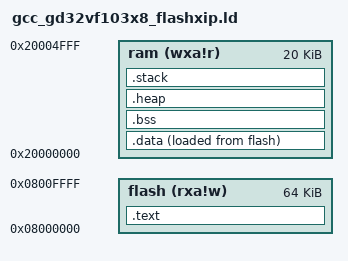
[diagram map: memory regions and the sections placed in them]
/*
 * Copyright (C) 2021 Sergey Koshkin <koshkin.sergey@gmail.com>
 * All rights reserved.
 *
 * SPDX-License-Identifier: Apache-2.0
 *
 * Licensed under the Apache License, Version 2.0 (the License); you may
 * not use this file except in compliance with the License.
 * You may obtain a copy of the License at
 *
 * www.apache.org/licenses/LICENSE-2.0
 *
 * Unless required by applicable law or agreed to in writing, software
 * distributed under the License is distributed on an AS IS BASIS, WITHOUT
 * WARRANTIES OR CONDITIONS OF ANY KIND, either express or implied.
 * See the License for the specific language governing permissions and
 * limitations under the License.
 */

/*********** Use Configuration Wizard in Context Menu *************************/

OUTPUT_ARCH( "riscv" )
/********************* Flash Configuration ************************************
 * <h> Flash Configuration
 * <o0> Flash Base Address <0x0-0xFFFFFFFF:8>
 * <o1> Flash Size (in Bytes) <0x0-0xFFFFFFFF:8>
 * </h>
 */
__ROM_BASE = 0x08000000;
__ROM_SIZE = 0x00010000;

/*--------------------- Embedded RAM Configuration ---------------------------
 * <h> RAM Configuration
 * <o0> RAM Base Address    <0x0-0xFFFFFFFF:8>
 * <o1> RAM Size (in Bytes) <0x0-0xFFFFFFFF:8>
 * </h>
*/
__RAM_BASE = 0x20000000;
__RAM_SIZE = 0x00005000;

/**************************** end of configuration section ********************/

ENTRY(_enter)

/* Define base address and length of flash and ram */
MEMORY
{
  flash (rxa!w) : ORIGIN = __ROM_BASE, LENGTH = __ROM_SIZE
  ram (wxa!r)   : ORIGIN = __RAM_BASE, LENGTH = __RAM_SIZE
}

REGION_ALIAS("ROM", flash)
REGION_ALIAS("RAM", ram)

SECTIONS
{
  /* To provide symbol __STACK_SIZE, __HEAP_SIZE */
  PROVIDE(__STACK_SIZE = 1K);
  PROVIDE(__HEAP_SIZE  = 0K);
  __TOT_STACK_SIZE = __STACK_SIZE;

  .text :
  {
    KEEP (*(.text.init))
    *(.text.unlikely .text.unlikely.*)
    *(.text.startup .text.startup.*)
    *(.text .text.*)
    *(.gnu.linkonce.t.*)

    KEEP(*(SORT_NONE(.init)))
    KEEP(*(SORT_NONE(.fini)))

    /* .ctors */
    *crtbegin.o(.ctors)
    *crtbegin?.o(.ctors)
    *(EXCLUDE_FILE(*crtend?.o *crtend.o) .ctors)
    *(SORT(.ctors.*))
    *(.ctors)

    /* .dtors */
    *crtbegin.o(.dtors)
    *crtbegin?.o(.dtors)
    *(EXCLUDE_FILE(*crtend?.o *crtend.o) .dtors)
    *(SORT(.dtors.*))
    *(.dtors)

    . = ALIGN(8);
    *(.srodata.cst16)
    *(.srodata.cst8)
    *(.srodata.cst4)
    *(.srodata.cst2)
    *(.srodata .srodata.*)
    *(.rdata)
    *(.rodata .rodata.*)
    *(.gnu.linkonce.r.*)

    /* copy.table */
    . = ALIGN(4);
    __copy_table_start__ = .;
    LONG (LOADADDR(.data))
    LONG (ADDR(.data))
    LONG (SIZEOF(.data) / 4)
    /* Add each additional data section here */
/*
    LONG (LOADADDR(.data2))
    LONG (ADDR(.data2))
    LONG (SIZEOF(.data2) / 4)
*/
    __copy_table_end__ = .;

    /* zero.table */
    . = ALIGN(4);
    __zero_table_start__ = .;
    /* Add each additional bss section here */
/*
    LONG (__bss2_start__)
    LONG ((__bss2_end__ - __bss2_start__) / 4)
*/
    __zero_table_end__ = .;

    KEEP(*(.eh_frame*))
  } > ROM

  PROVIDE (__etext = .);

  .data            : ALIGN(8)
  {
    KEEP(*(.data.ctest*))
    *(.data .data.*)
    *(.gnu.linkonce.d.*)
    . = ALIGN(8);
    PROVIDE( __global_pointer$ = . + 0x800 );
    *(.sdata .sdata.* .sdata*)
    *(.gnu.linkonce.s.*)
    . = ALIGN(8);
  } >RAM AT>ROM

  .bss (NOLOAD)   : ALIGN(8)
  {
    PROVIDE( __bss_start = . );
    *(.sbss*)
    *(.gnu.linkonce.sb.*)
    *(.bss .bss.*)
    *(.gnu.linkonce.b.*)
    *(COMMON)
    . = ALIGN(4);
    PROVIDE( _end = . );
  } >RAM AT>RAM

  /* Nuclei C Runtime Library requirements:
   * 1. heap need to be align at 16 bytes
   * 2. __heap_start and __heap_end symbol need to be defined
   * 3. reserved at least __HEAP_SIZE space for heap
   */
  .heap (NOLOAD)   : ALIGN(16)
  {
    . = ALIGN(16);
    PROVIDE( __heap_start = . );
    . += __HEAP_SIZE;
    . = ALIGN(16);
    PROVIDE( __heap_limit = . );
  } >RAM

  .stack ORIGIN(RAM) + LENGTH(RAM) - __TOT_STACK_SIZE (NOLOAD) :
  {
    . = ALIGN(16);
    PROVIDE( _heap_end = . );
    PROVIDE( __heap_end = . );
    PROVIDE( __StackLimit = . );
    PROVIDE( __StackBottom = . );
    . += __TOT_STACK_SIZE;
    . = ALIGN(16);
    PROVIDE( __StackTop = . );
    PROVIDE( _sp = . );
  } >RAM
}
